# GPMC register map
Vendor: Texas Instruments
Peripheral module from a debugger description file (folder 66AK2G0x_66AK2G1x).
Registers are 32-bit, read-write, reset 0x0 unless marked. A register's access mark holds for its fields unless they carry their own. Offsets are as the file gives them; lines under a group give offsets from that group; [hi:lo] are bit positions; {n}, {i} and the like mark numbered series; 'fields as' and 'values as' point back to an identical list; <NAME> marks a mode.

## GPMC
0x00 GPMC_REVISION ro reset 0x60
  [31:0] REVISION — TI internal data. Identifies revision of peripheral.
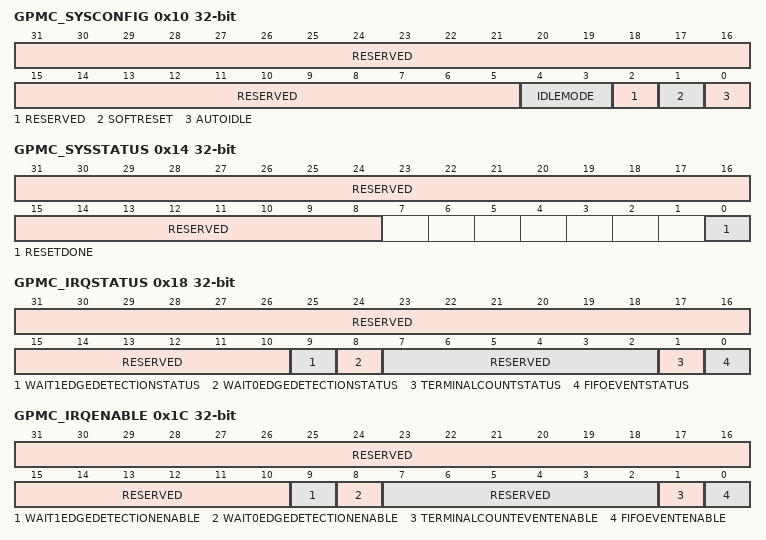
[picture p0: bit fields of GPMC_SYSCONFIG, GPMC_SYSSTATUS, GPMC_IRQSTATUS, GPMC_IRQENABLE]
0x10 GPMC_SYSCONFIG
  [31:5] RESERVED — Write 0s for future compatibility. Read returns 0.
  [4:3] IDLEMODE — 0h: Force-idle. An idle request is acknowledged unconditionally. 1h (R/W) = No-idle. An idle request is never acknowledged. 2h (R/W) = Smart-idle. Acknowledgment to an idle request is given based on the internal activity of the module. 3h (R/W) = Reserved. Do not use.
  [2] RESERVED — Write 0 for future compatibility Read returns 0.
  [1] SOFTRESET — Software reset. 0h (R/W) = Normal mode 1h (R/W) = The module is reset.
  [0] AUTOIDLE — Internal interface clock-gating strategy 0h (R/W) = Interface clock is free-running. 1h (R/W) = Automatic Interface clock gating strategy is applied, based on the interconnect activity.
0x14 GPMC_SYSSTATUS ro (reset mask 0xFFFFFFFE)
  [31:8] RESERVED — Read returns 0.
  [0] RESETDONE — Internal reset monitoring 0h (R) = Internal module reset is ongoing. 1h (R) = Reset is complete.
0x18 GPMC_IRQSTATUS
  [31:10] RESERVED — Write 0s for future compatibility. Read returns 0s.
  [9] WAIT1EDGEDETECTIONSTATUS — Status of the Wait1 Edge Detection interrupt Write: 0h = WAIT1EDGEDETECTIONSTATUS bit is unchanged. 1h = WAIT1EDGEDETECTIONSTATUS bit is reset. Read: 0h = A transition on WAIT1 input pin has not been detected. 1h = A transition on WAIT1 input pin has been detected.
  [8] WAIT0EDGEDETECTIONSTATUS — Status of the Wait0 Edge Detection interrupt Write: 0h = WAIT0EDGEDETECTIONSTATUS bit is unchanged. 1h = WAIT0EDGEDETECTIONSTATUS bit is reset. Read: 0h = A transition on WAIT0 input pin has not been detected. 1h = A transition on WAIT0 input pin has been detected.
  [7:2] RESERVED — Write 0s for future compatibility. Read returns 0s.
  [1] TERMINALCOUNTSTATUS — Status of the TerminalCountEvent interrupt Write: 0h = TERMINALCOUNTSTATUS bit is unchanged. 1h = TERMINALCOUNTSTATUS bit is reset. Read: 0h = Indicates that CountValue is greater than 0. 1h = Indicates that CountValue is equal to 0.
  [0] FIFOEVENTSTATUS — Status of the FIFOEvent interrupt Write: 0h = FIFOEVENTSTATUS bit is unchanged. 1h = FIFOEVENTSTATUS bit is reset. Read: 0h = Indicates that less than 1h = Indicates that at least
0x1C GPMC_IRQENABLE
  [31:10] RESERVED — Write 0s for future compatibility. Read returns 0s.
  [9] WAIT1EDGEDETECTIONENABLE — Enables the Wait1 Edge Detection interrupt 0h (R/W) = Wait1EdgeDetection interrupt is masked. 1h (R/W) = Wait1EdgeDetection event generates an interrupt if occurs.
  [8] WAIT0EDGEDETECTIONENABLE — Enables the Wait0 Edge Detection interrupt 0h (R/W) = Wait0EdgeDetection interrupt is masked. 1h (R/W) = Wait0EdgeDetection event generates an interrupt if occurs.
  [7:2] RESERVED — Write 0s for future compatibility. Read returns 0s.
  [1] TERMINALCOUNTEVENTENABLE — Enables TerminalCountEvent interrupt issuing in prefetch or write-posting mode 0h (R/W) = TerminalCountEvent interrupt is masked. 1h (R/W) = TerminalCountEvent interrupt is not masked.
  [0] FIFOEVENTENABLE — Enables the FIFOEvent interrupt 0h (R/W) = FIFOEvent interrupt is masked. 1h (R/W) = FIFOEvent interrupt is not masked.
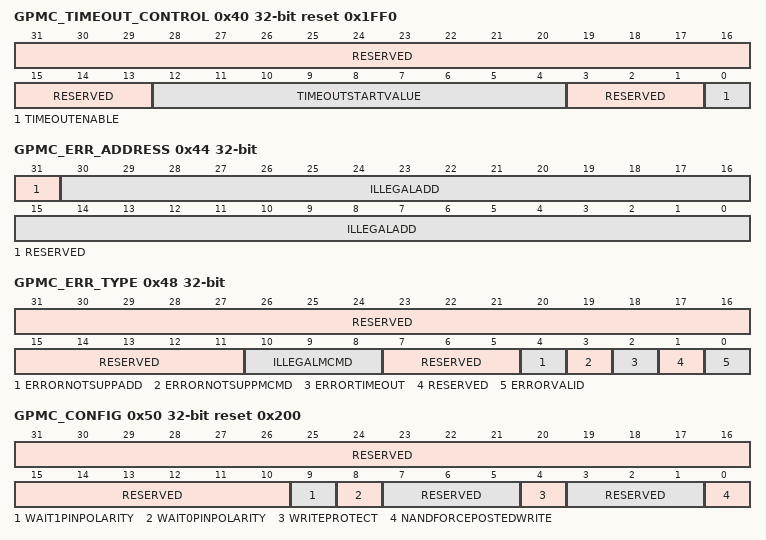
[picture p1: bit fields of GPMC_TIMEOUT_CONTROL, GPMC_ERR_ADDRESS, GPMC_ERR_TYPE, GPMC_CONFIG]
0x40 GPMC_TIMEOUT_CONTROL reset 0x1FF0
  [31:13] RESERVED — Write 0s for future compatibility. Read returns 0s.
  [12:4] TIMEOUTSTARTVALUE — Start value of the time-out counter
  [3:1] RESERVED — Write 0s for future compatibility. Read returns 0s.
  [0] TIMEOUTENABLE — Enable bit of the TimeOut feature 0h (R/W) = TimeOut feature is disabled. 1h (R/W) = TimeOut feature is enabled.
0x44 GPMC_ERR_ADDRESS access per field
  [31] RESERVED rw — Write 0s for future compatibility. Read returns 0.
  [30:0] ILLEGALADD ro — Address of illegal access
0x48 GPMC_ERR_TYPE access per field
  [31:11] RESERVED rw — Write 0s for future compatibility. Read returns 0s.
  [10:8] ILLEGALMCMD ro — System command of the transaction that caused the error
  [7:5] RESERVED rw — Write 0s for future compatibility. Read returns 0s.
  [4] ERRORNOTSUPPADD ro — Not supported address error 0h (R) = No error occurs. 1h (R) = The error is due to a nonsupported address.
  [3] ERRORNOTSUPPMCMD ro — Not supported command error 0h (R) = No error occurs. 1h (R) = The error is due to a nonsupported command
  [2] ERRORTIMEOUT ro — Time-out error 0h (R) = No error occurs. 1h (R) = The error is due to a timeout.
  [1] RESERVED rw — Write 0s for future compatibility. Read returns 0.
  [0] ERRORVALID rw — Error validity status - Must be explicitly cleared with a write 1 transaction 0h (R/W) = All error fields no longer valid 1h (R/W) = Error detected and logged in the other error fields
0x50 GPMC_CONFIG reset 0x200
  [31:10] RESERVED — Write 0s for future compatibility. Read returns 0s.
  [9] WAIT1PINPOLARITY — Selects the polarity of input pin WAIT1 0h (R/W) = WAIT1 active low 1h (R/W) = WAIT1 active high
  [8] WAIT0PINPOLARITY — Selects the polarity of input pin WAIT0 0h (R/W) = WAIT0 active low 1h (R/W) = WAIT0 active high
  [7:5] RESERVED — Write 0s for future compatibility. Read returns 0s.
  [4] WRITEPROTECT — Controls the WP output pin level 0h (R/W) = nWP output pin is low 1h (R/W) = nWP output pin is high
  [3:1] RESERVED — Write 0s for future compatibility. Read returns 0s.
  [0] NANDFORCEPOSTEDWRITE — Enables the Force Posted Write feature to NAND Cmd/Add/Data location 0h (R/W) = Disables Force Posted Write 1h (R/W) = Enables Force Posted Write
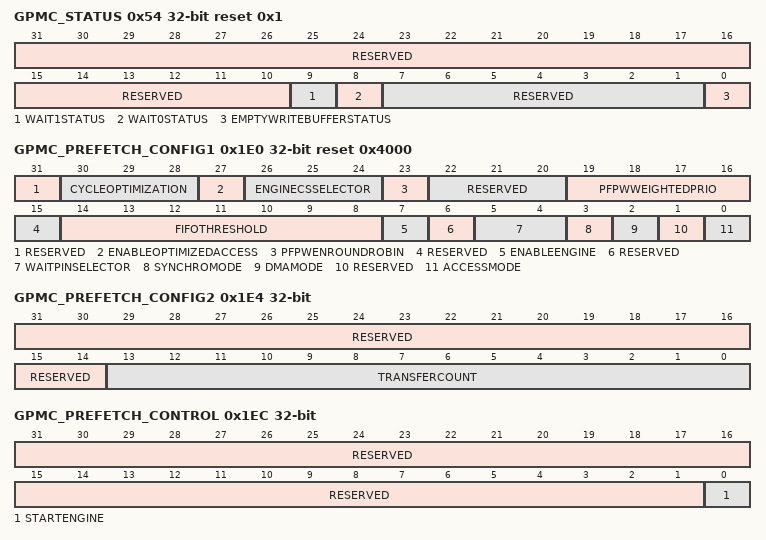
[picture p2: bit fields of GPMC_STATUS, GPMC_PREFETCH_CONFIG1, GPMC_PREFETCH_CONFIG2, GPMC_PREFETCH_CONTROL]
0x54 GPMC_STATUS access per field reset 0x1 (reset mask 0xFFFFFCFF)
  [31:10] RESERVED rw — Write 0s for future compatibility. Read returns 0s.
  [9] WAIT1STATUS ro — Is a copy of input pin WAIT1. (Reset value is WAIT1 input pin sampled at device reset.) 0h (R) = WAIT1 asserted (inactive state) 1h (R) = WAIT1 deasserted
  [8] WAIT0STATUS ro — Is a copy of input pin WAIT0. (Reset value is WAIT0 input pin sampled at device reset.) 0h (R) = WAIT0 asserted (inactive state) 1h (R) = WAIT0 deasserted
  [7:1] RESERVED rw — Write 0s for future compatibility. Reads returns 0
  [0] EMPTYWRITEBUFFERSTATUS ro — Stores the empty status of the write buffer 0h (R) = Write buffer is not empty. 1h (R) = Write buffer is empty.
0x1E0 GPMC_PREFETCH_CONFIG1 reset 0x4000
  [31] RESERVED — Write 0s for future compatibility. Read returns 0.
  [30:28] CYCLEOPTIMIZATION — Define the number of GPMC_FCLK cycles to be subtracted from RDCYCLETIME, WRCYCLETIME, RDACCESSTIME, CSRDOFFTIME, CSWROFFTIME, ADVRDOFFTIME, ADVWROFFTIME, OEOFFTIME, WEOFFTIME
  [27] ENABLEOPTIMIZEDACCESS — Enables access cycle optimization 0h (R/W) = Access cycle optimization is disabled. 1h (R/W) = Access cycle optimization is enabled.
  [26:24] ENGINECSSELECTOR — Selects the chip-select where Prefetch Postwrite engine is active
  [23] PFPWENROUNDROBIN — Enables the PFPW RoundRobin arbitration 0h (R/W) = Prefetch Postwrite engine round robin arbitration is disabled. 1h (R/W) = Prefetch Postwrite engine round robin arbitration is enabled.
  [22:20] RESERVED — Write 0s for future compatibility. Read returns 0s.
  [19:16] PFPWWEIGHTEDPRIO — When an arbitration occurs between a DMA and a PFPW engine access, the DMA is always serviced. If the PFPWEnRoundRobin is enabled,
  [15] RESERVED — Write 0s for future compatibility. Read returns 0.
  [14:8] FIFOTHRESHOLD — Selects the maximum number of bytes read from the FIFO or written to the FIFO by the host on a DMA or interrupt request
  [7] ENABLEENGINE — Enables the Prefetch Postwite engine 0h (R/W) = Prefetch Postwrite engine is disabled. 1h (R/W) = Prefetch Postwrite engine is enabled.
  [6] RESERVED — Write 0s for future compatibility. Read returns 0.
  [5:4] WAITPINSELECTOR — Select which wait pin edge detector should start the engine in synchronized mode 0h (R/W) = Selects Wait0 EdgeDetection 1h (R/W) = Selects Wait1 EdgeDetection2h, 3h: Reserved
  [3] SYNCHROMODE — Selects when the engine starts the access to chip-select 0h (R/W) = Engine starts the access to chip-select as soon as STARTENGINE is set 1h (R/W) = Engine starts the access to chip-select as soon as STARTENGINE is set AND wait to nonwait edge detection on the selected wait pin
  [2] DMAMODE — Selects interrupt synchronization or DMA request synchronization 0h (R/W) = Interrupt synchronization is enabled. Only interrupt line is activated on FIFO threshold crossing. 1h (R/W) = DMA request synchronization is enabled. A DMA request protocol is used.
  [1] RESERVED — Write 0s for future compatibility. Read returns 0.
  [0] ACCESSMODE — Selects prefetch read or write-posting accesses 0h (R/W) = Prefetch read mode 1h (R/W) = Write-posting mode
0x1E4 GPMC_PREFETCH_CONFIG2
  [31:14] RESERVED — Write 0s for future compatibility. Read returns 0s.
  [13:0] TRANSFERCOUNT — Selects the number of bytes to be read or written by the engine to the selected chip-select
0x1EC GPMC_PREFETCH_CONTROL
  [31:1] RESERVED — Write 0s for future compatibility. Read returns 0s.
  [0] STARTENGINE — Resets the FIFO pointer and starts the engine Write: 0h = Stops the engine. 1h = Resets the FIFO pointer to 0h in prefetch mode and 40h in postwrite mode and starts the engine. Read: 0h = Engine is stopped. 1h = Engine is running.
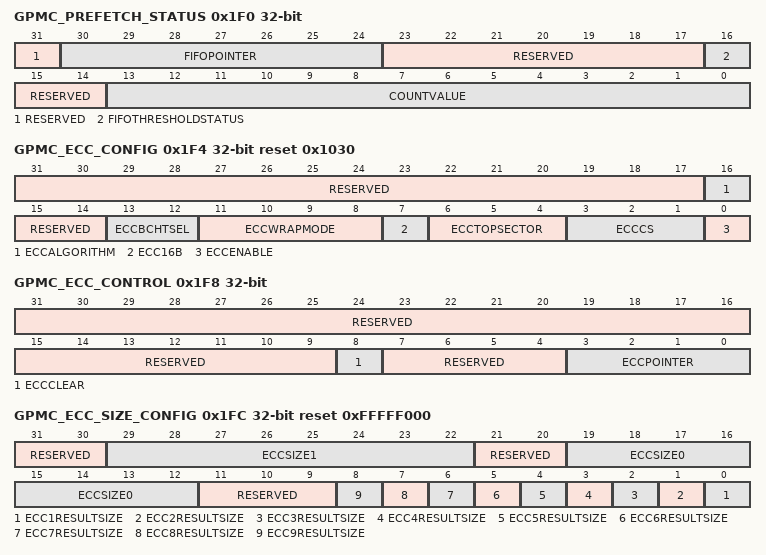
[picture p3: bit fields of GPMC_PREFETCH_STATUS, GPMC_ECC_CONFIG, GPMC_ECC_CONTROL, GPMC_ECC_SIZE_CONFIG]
0x1F0 GPMC_PREFETCH_STATUS access per field
  [31] RESERVED rw — Write 0s for future compatibility. Read returns 0.
  [30:24] FIFOPOINTER ro — Number of available bytes to be read or number of free empty byte places to be written
  [23:17] RESERVED rw — Write 0s for future compatibility. Read returns 0s.
  [16] FIFOTHRESHOLDSTATUS ro — Set when FIFOPointer exceeds FIFOThreshold value 0h (R) = FIFOPointer smaller or equal to FIFOThreshold. Writing to this bit has no effect. 1h (R) = FIFOPointer greater than FIFOThreshold. Writing to this bit has no effect.
  [15:14] RESERVED rw — Write 0s for future compatibility. Read returns 0s.
  [13:0] COUNTVALUE ro — Number of remaining bytes to be read or to be written by the engine according to the TransferCount value
0x1F4 GPMC_ECC_CONFIG reset 0x1030
  [31:17] RESERVED — Write 0s for future compatibility. Read returns 0s.
  [16] ECCALGORITHM — ECC algorithm used 0h (R/W) = Hamming code 1h (R/W) = BCH code
  [15:14] RESERVED — Write 0s for future compatibility. Read returns 0s.
  [13:12] ECCBCHTSEL — Error correction capability used for BCH 0h (R/W) = Up to 4 bits error correction (t = 4) 1h (R/W) = Up to 8 bits error correction (t = 8) 2h (R/W) = Up to 16 bits error correction (t = 16) 3h (R/W) = Reserved
  [11:8] ECCWRAPMODE — Spare area organization definition for the BCH algorithm. See the BCH syndrome/parity calculator module functional specification for more details
  [7] ECC16B — Selects an ECC calculated on 16 columns 0h (R/W) = ECC calculated on 8 columns 1h (R/W) = ECC calculated on 16 columns
  [6:4] ECCTOPSECTOR — Number of sectors to process with the BCH algorithm 1h: 2 sectors
  [3:1] ECCCS — Selects the CS where ECC is computed 0h (R/W) = CS0 1h (R/W) = CS1 2h (R/W) = CS2 3h (R/W) = CS3 Other: Reserved
  [0] ECCENABLE — Enables the ECC feature 0h (R/W) = ECC disabled 1h (R/W) = ECC enabled
0x1F8 GPMC_ECC_CONTROL
  [31:9] RESERVED — Write 0s for future compatibility. Read returns 0s.
  [8] ECCCLEAR — Clear all ECC result registers
  [7:4] RESERVED — Write 0s for future compatibility. Read returns 0s.
  [3:0] ECCPOINTER — Selects ECC result register (Reads to this field give the dynamic position of the ECC pointer - Writes to this field select the ECC result register where the first ECC computation will be stored.); Writing other values disables the ECC engine (ECCENABLE bit of 0h (R/W) = Writing 0h disables the ECC engine (ECCENABLE bit of 1h (R/W) = ECC result register 1 selected 2h (R/W) = ECC result register 2 selected 3h (R/W) = ECC result register 3 selected 4h (R/W) = ECC result register 4 selected 5h (R/W) = ECC result register 5 selected 6h (R/W) = ECC result register 6 selected 7h (R/W) = ECC result register 7 selected 8h (R/W) = ECC result register 8 selected 9h (R/W) = ECC result register 9 selected
0x1FC GPMC_ECC_SIZE_CONFIG reset 0xFFFFF000
  [31:30] RESERVED — Write 0s for future compatibility. Read returns 3.
  [29:22] ECCSIZE1 — Defines Hamming code ECC size 1 in bytes
  [21:20] RESERVED — Write 0s for future compatibility. Read returns 3.
  [19:12] ECCSIZE0 — Defines Hamming code ECC size 0 in bytes
  [11:9] RESERVED — Write 0s for future compatibility. Read returns 0s.
  [n-1] ECC{n}RESULTSIZE (n=1..9) — Selects ECC size for ECC {n} result register 0h (R/W) = ECCSIZE0 selected 1h (R/W) = ECCSIZE1 selected
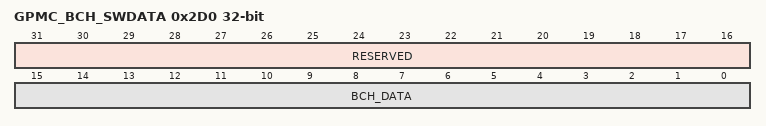
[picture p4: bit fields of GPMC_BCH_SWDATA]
0x2D0 GPMC_BCH_SWDATA access per field
  [31:16] RESERVED ro — Write 0s for future compatibility. Read returns 0s.
  [15:0] BCH_DATA rw — Data to be included in the BCH calculation
